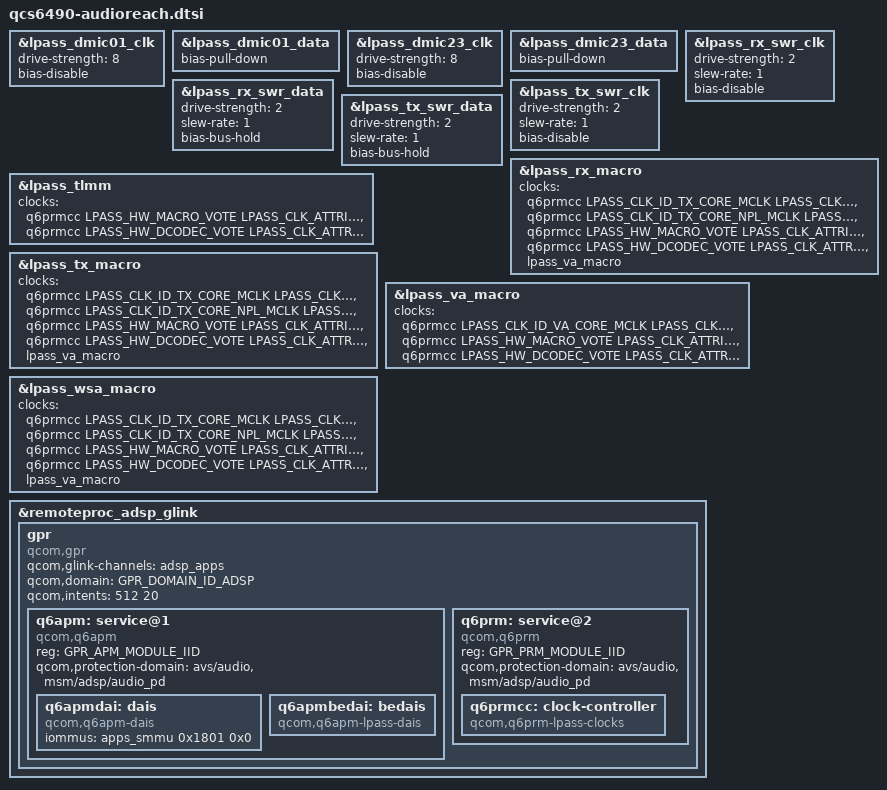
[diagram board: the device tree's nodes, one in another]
// SPDX-License-Identifier: GPL-2.0-only
/*
 * qcs6490 device tree source for Audioreach Solution.
 * This file will handle the common audio device tree nodes.
 *
 * Copyright (c) 2025 Qualcomm Innovation Center, Inc. All rights reserved.
 */

#include <dt-bindings/clock/qcom,lpass-sc7280.h>
#include <dt-bindings/soc/qcom,gpr.h>
#include <dt-bindings/sound/qcom,q6afe.h>
#include <dt-bindings/sound/qcom,q6dsp-lpass-ports.h>

&lpass_dmic01_clk {
	drive-strength = <8>;
	bias-disable;
};

&lpass_dmic01_data {
	bias-pull-down;
};

&lpass_dmic23_clk {
	drive-strength = <8>;
	bias-disable;
};

&lpass_dmic23_data {
	bias-pull-down;
};

&lpass_rx_swr_clk {
	drive-strength = <2>;
	slew-rate = <1>;
	bias-disable;
};

&lpass_rx_swr_data {
	drive-strength = <2>;
	slew-rate = <1>;
	bias-bus-hold;
};

&lpass_tx_swr_clk {
	drive-strength = <2>;
	slew-rate = <1>;
	bias-disable;
};

&lpass_tx_swr_data {
	drive-strength = <2>;
	slew-rate = <1>;
	bias-bus-hold;
};

&lpass_rx_macro {
	/delete-property/ power-domains;
	/delete-property/ power-domain-names;
	clocks = <&q6prmcc LPASS_CLK_ID_TX_CORE_MCLK LPASS_CLK_ATTRIBUTE_COUPLE_NO>,
		 <&q6prmcc LPASS_CLK_ID_TX_CORE_NPL_MCLK  LPASS_CLK_ATTRIBUTE_COUPLE_NO>,
		 <&q6prmcc LPASS_HW_MACRO_VOTE LPASS_CLK_ATTRIBUTE_COUPLE_NO>,
		 <&q6prmcc LPASS_HW_DCODEC_VOTE LPASS_CLK_ATTRIBUTE_COUPLE_NO>,
		 <&lpass_va_macro>;
	clock-names = "mclk",
		      "npl",
		      "macro",
		      "dcodec",
		      "fsgen";
};

&lpass_tlmm {
	clocks = <&q6prmcc LPASS_HW_MACRO_VOTE LPASS_CLK_ATTRIBUTE_COUPLE_NO>,
		 <&q6prmcc LPASS_HW_DCODEC_VOTE LPASS_CLK_ATTRIBUTE_COUPLE_NO>;
	clock-names = "core",
		      "audio";
};

&lpass_tx_macro {
	/delete-property/ power-domains;
	/delete-property/ power-domain-names;
	clocks = <&q6prmcc LPASS_CLK_ID_TX_CORE_MCLK LPASS_CLK_ATTRIBUTE_COUPLE_NO>,
		 <&q6prmcc LPASS_CLK_ID_TX_CORE_NPL_MCLK  LPASS_CLK_ATTRIBUTE_COUPLE_NO>,
		 <&q6prmcc LPASS_HW_MACRO_VOTE LPASS_CLK_ATTRIBUTE_COUPLE_NO>,
		 <&q6prmcc LPASS_HW_DCODEC_VOTE LPASS_CLK_ATTRIBUTE_COUPLE_NO>,
		 <&lpass_va_macro>;
	clock-names = "mclk",
		      "npl",
		      "macro",
		      "dcodec",
		      "fsgen";
};

&lpass_va_macro {
	/delete-property/ power-domains;
	/delete-property/ power-domain-names;
	clocks = <&q6prmcc LPASS_CLK_ID_VA_CORE_MCLK LPASS_CLK_ATTRIBUTE_COUPLE_NO>,
		 <&q6prmcc LPASS_HW_MACRO_VOTE LPASS_CLK_ATTRIBUTE_COUPLE_NO>,
		 <&q6prmcc LPASS_HW_DCODEC_VOTE LPASS_CLK_ATTRIBUTE_COUPLE_NO>;
	clock-names = "mclk",
		      "macro",
		      "dcodec";
};

&lpass_wsa_macro {
	/delete-property/ power-domains;
	/delete-property/ power-domain-names;
	clocks = <&q6prmcc LPASS_CLK_ID_TX_CORE_MCLK LPASS_CLK_ATTRIBUTE_COUPLE_NO>,
		 <&q6prmcc LPASS_CLK_ID_TX_CORE_NPL_MCLK LPASS_CLK_ATTRIBUTE_COUPLE_NO>,
		 <&q6prmcc LPASS_HW_MACRO_VOTE LPASS_CLK_ATTRIBUTE_COUPLE_NO>,
		 <&q6prmcc LPASS_HW_DCODEC_VOTE LPASS_CLK_ATTRIBUTE_COUPLE_NO>,
		 <&lpass_va_macro>;
	clock-names = "mclk",
		      "npl",
		      "macro",
		      "dcodec",
		      "fsgen";
};

&remoteproc_adsp_glink {
	/delete-node/ apr;

	gpr {
		compatible = "qcom,gpr";
		qcom,glink-channels = "adsp_apps";
		qcom,domain = <GPR_DOMAIN_ID_ADSP>;
		qcom,intents = <512 20>;
		#address-cells = <1>;
		#size-cells = <0>;

		q6apm: service@1 {
			compatible = "qcom,q6apm";
			reg = <GPR_APM_MODULE_IID>;
			#sound-dai-cells = <0>;
			qcom,protection-domain = "avs/audio", "msm/adsp/audio_pd";

			q6apmdai: dais {
				compatible = "qcom,q6apm-dais";
				iommus = <&apps_smmu 0x1801 0x0>;
			};

			q6apmbedai: bedais {
				compatible = "qcom,q6apm-lpass-dais";
				#sound-dai-cells = <1>;
			};
		};

		q6prm: service@2 {
			compatible = "qcom,q6prm";
			reg = <GPR_PRM_MODULE_IID>;
			qcom,protection-domain = "avs/audio", "msm/adsp/audio_pd";

			q6prmcc: clock-controller {
				compatible = "qcom,q6prm-lpass-clocks";
				#clock-cells = <2>;
			};
		};
	};
};
